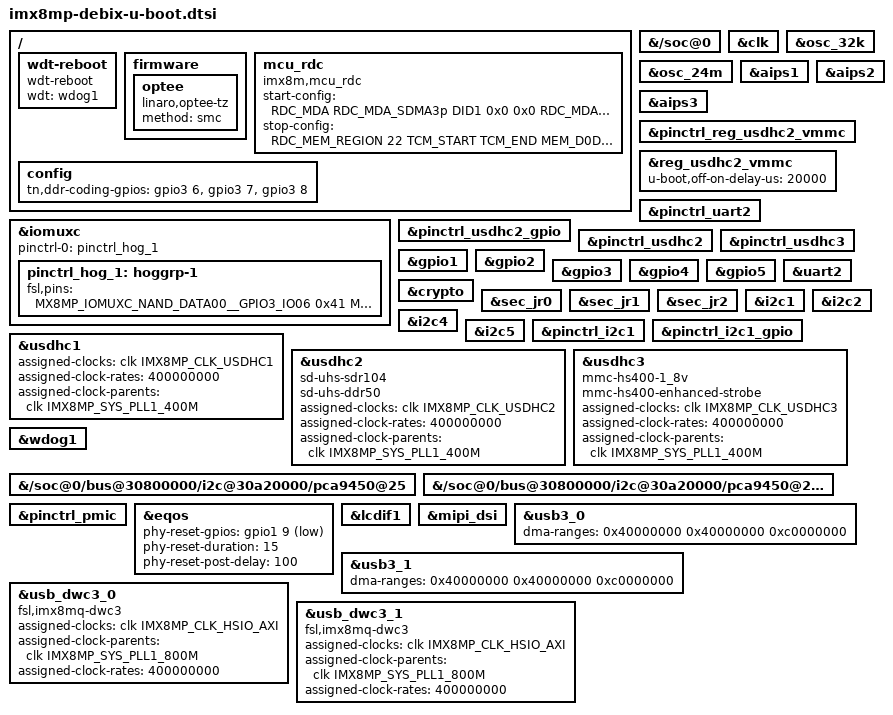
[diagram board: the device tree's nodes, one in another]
// SPDX-License-Identifier: GPL-2.0+
/*
 * Copyright 2019 NXP
 * Copyright 2020 Technexion Ltd.
 */
#include "imx8mp-sec-def.h"

/ {
	wdt-reboot {
		compatible = "wdt-reboot";
		wdt = <&wdog1>;
		bootph-pre-ram;
	};

	firmware {
		optee {
			compatible = "linaro,optee-tz";
			method = "smc";
		};
	};

	mcu_rdc {
		compatible = "imx8m,mcu_rdc";
			    /* rdc config when MCU starts
			     * master
			     *   SDMA3p --> domain 1
			     *   SDMA3b --> domian 1
			     *   SDMA3_SPBA2  --> domian 1
			     * peripheral:
			     *   SAI3   --> Only Domian 1 can access
			     *   UART4  --> Only Domian 1 can access
			     *   GPT1   --> Only Domian 1 can access
			     *   SDMA3  --> Only Domian 1 can access
			     *   I2C3   --> Only Domian 1 can access
			     * memory:
			     *   TCM    --> Only Domian 1 can access (0x7E0000~0x81FFFF)
			     *   DDR    --> Only Domian 1 can access (0x80000000~0x81000000)
			     * end.
			     */
		start-config = <
			    RDC_MDA  RDC_MDA_SDMA3p DID1 0x0 0x0
			    RDC_MDA  RDC_MDA_SDMA3b DID1 0x0 0x0
			    RDC_MDA  RDC_MDA_SDMA3_SPBA2 DID1 0x0 0x0
			    RDC_PDAP RDC_PDAP_SAI3  PDAP_D1_ACCESS 0x0 0x0
			    RDC_PDAP RDC_PDAP_UART4 PDAP_D1_ACCESS 0x0 0x0
			    RDC_PDAP RDC_PDAP_GPT1  PDAP_D1_ACCESS 0x0 0x0
			    RDC_PDAP RDC_PDAP_SDMA3 PDAP_D1_ACCESS 0x0 0x0
			    RDC_PDAP RDC_PDAP_I2C3  PDAP_D1_ACCESS 0x0 0x0
			    RDC_MEM_REGION 22 TCM_START TCM_END MEM_D1_ACCESS
			    RDC_MEM_REGION 39 M4_DDR_START M4_DDR_END MEM_D1_ACCESS
			    0x0      0x0            0x0  0x0 0x0
			  >;
			    /* rdc config when MCU stops
			     * memory:
			     *   TCM    --> domain 0/1 can access (0x7E0000~0x81FFFF)
			     *   DDR    --> domain 0/1 can access (0x80000000~0x81000000)
			     * end.
			     */
		stop-config = <
			    RDC_MEM_REGION 22 TCM_START TCM_END MEM_D0D1_ACCESS
			    RDC_MEM_REGION 39 M4_DDR_START M4_DDR_END MEM_D0D1_ACCESS
			    0x0      0x0            0x0  0x0 0x0
			  >;
	};

	config {
				      /* BOARD_ID0   BOARD_ID1  BOARD_ID2 */
		tn,ddr-coding-gpios = <&gpio3 6 0>, <&gpio3 7 0>, <&gpio3 8 0>;
	};
};

&{/soc@0} {
	bootph-all;
	bootph-pre-ram;
};

&clk {
	bootph-pre-ram;
	bootph-all;
	/delete-property/ assigned-clocks;
	/delete-property/ assigned-clock-parents;
	/delete-property/ assigned-clock-rates;

};

&osc_32k {
	bootph-pre-ram;
	bootph-all;
};

&osc_24m {
	bootph-pre-ram;
	bootph-all;
};

&aips1 {
	bootph-pre-ram;
	bootph-all;
};

&aips2 {
	bootph-pre-ram;
};

&aips3 {
	bootph-pre-ram;
};

&iomuxc {
	bootph-pre-ram;
	pinctrl-0 = <&pinctrl_hog_1>;

	pinctrl_hog_1: hoggrp-1 {
		fsl,pins = <
			MX8MP_IOMUXC_NAND_DATA00__GPIO3_IO06		0x41
			MX8MP_IOMUXC_NAND_DATA01__GPIO3_IO07		0x41
			MX8MP_IOMUXC_NAND_DATA02__GPIO3_IO08		0x41
		>;
	};
};

&pinctrl_reg_usdhc2_vmmc {
	bootph-pre-ram;
};

&reg_usdhc2_vmmc {
	bootph-pre-ram;
	u-boot,off-on-delay-us = <20000>;
};

&pinctrl_uart2 {
	bootph-pre-ram;
};

&pinctrl_usdhc2_gpio {
	bootph-pre-ram;
};

&pinctrl_usdhc2 {
	bootph-pre-ram;
};

&pinctrl_usdhc3 {
	bootph-pre-ram;
};

&gpio1 {
	bootph-pre-ram;
};

&gpio2 {
	bootph-pre-ram;
};

&gpio3 {
	bootph-pre-ram;
};

&gpio4 {
	bootph-pre-ram;
};

&gpio5 {
	bootph-pre-ram;
};

&uart2 {
	bootph-pre-ram;
};

&crypto {
	bootph-pre-ram;
};

&sec_jr0 {
	bootph-pre-ram;
};

&sec_jr1 {
	bootph-pre-ram;
};

&sec_jr2 {
	bootph-pre-ram;
};

&i2c1 {
	bootph-pre-ram;
};

&i2c2 {
	bootph-pre-ram;
};

&i2c4 {
	bootph-pre-ram;
};

&i2c5 {
	bootph-pre-ram;
};

&pinctrl_i2c1 {
	bootph-pre-ram;
};

&pinctrl_i2c1_gpio {
	bootph-pre-ram;
};

&usdhc1 {
	bootph-pre-ram;
	assigned-clocks = <&clk IMX8MP_CLK_USDHC1>;
	assigned-clock-rates = <400000000>;
	assigned-clock-parents = <&clk IMX8MP_SYS_PLL1_400M>;
};

&usdhc2 {
	bootph-pre-ram;
	sd-uhs-sdr104;
	sd-uhs-ddr50;
	assigned-clocks = <&clk IMX8MP_CLK_USDHC2>;
	assigned-clock-rates = <400000000>;
	assigned-clock-parents = <&clk IMX8MP_SYS_PLL1_400M>;
};

&usdhc3 {
	bootph-pre-ram;
	mmc-hs400-1_8v;
	mmc-hs400-enhanced-strobe;
	assigned-clocks = <&clk IMX8MP_CLK_USDHC3>;
	assigned-clock-rates = <400000000>;
	assigned-clock-parents = <&clk IMX8MP_SYS_PLL1_400M>;
};

&wdog1 {
	bootph-pre-ram;
};

&{/soc@0/bus@30800000/i2c@30a20000/pca9450@25} {
	bootph-pre-ram;
};

&{/soc@0/bus@30800000/i2c@30a20000/pca9450@25/regulators} {
	bootph-pre-ram;
};

&pinctrl_pmic {
	bootph-pre-ram;
};

&eqos {
	phy-reset-gpios = <&gpio1 9 GPIO_ACTIVE_LOW>;
	phy-reset-duration = <15>;
	phy-reset-post-delay = <100>;
};

&lcdif1 {
	/delete-property/ assigned-clocks;
	/delete-property/ assigned-clock-parents;
	/delete-property/ assigned-clock-rates;
};

&mipi_dsi {
	/delete-property/ assigned-clocks;
	/delete-property/ assigned-clock-parents;
	/delete-property/ assigned-clock-rates;
};

&usb3_0 {
	dma-ranges = <0x40000000 0x40000000 0xc0000000>;
	/delete-property/ power-domains;
};

&usb3_1 {
	dma-ranges = <0x40000000 0x40000000 0xc0000000>;
	/delete-property/ power-domains;
};

&usb_dwc3_0 {
	compatible = "fsl,imx8mq-dwc3", "snps,dwc3";
	assigned-clocks = <&clk IMX8MP_CLK_HSIO_AXI>;
	assigned-clock-parents = <&clk IMX8MP_SYS_PLL1_800M>;
	assigned-clock-rates = <400000000>;
};

&usb_dwc3_1 {
	compatible = "fsl,imx8mq-dwc3", "snps,dwc3";
	assigned-clocks = <&clk IMX8MP_CLK_HSIO_AXI>;
	assigned-clock-parents = <&clk IMX8MP_SYS_PLL1_800M>;
	assigned-clock-rates = <400000000>;
};
